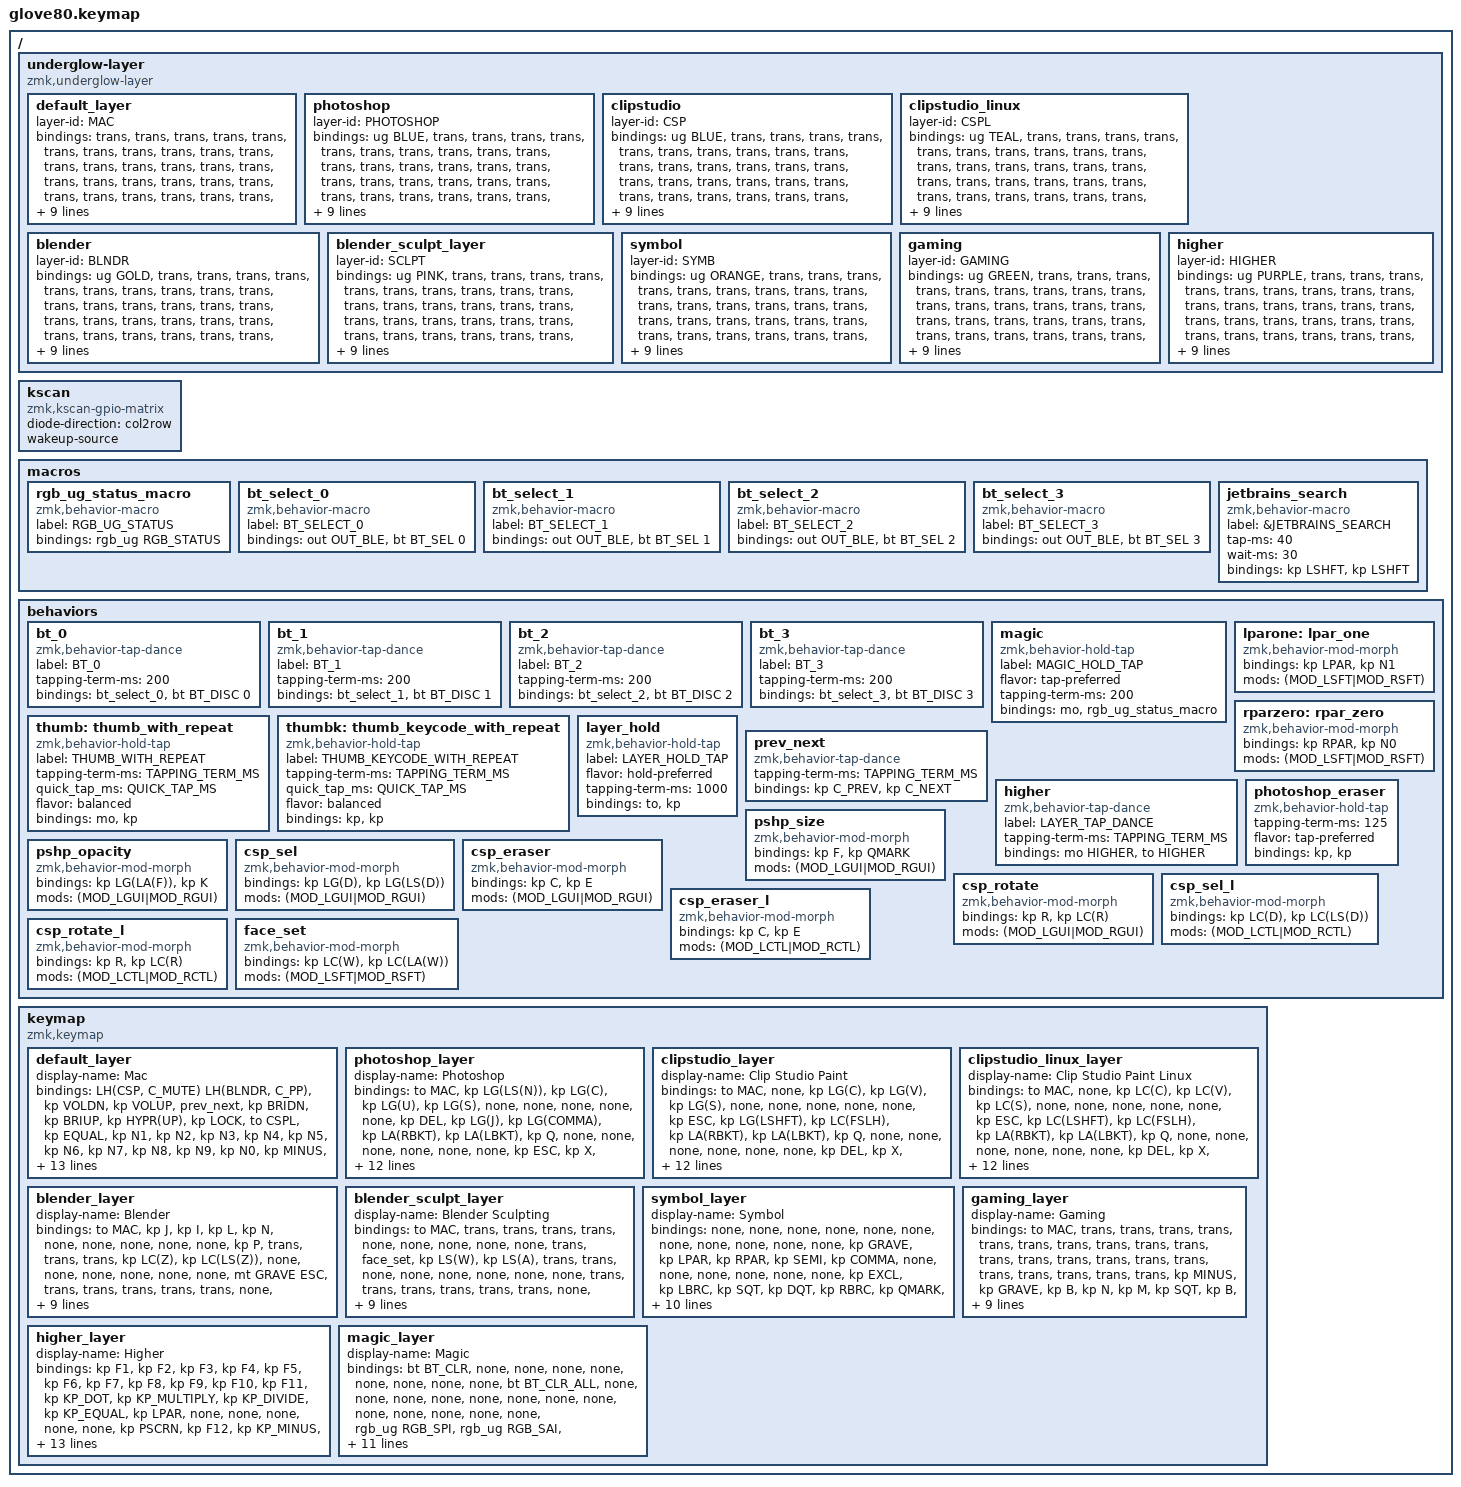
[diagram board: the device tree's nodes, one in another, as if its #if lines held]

/*
 * Copyright (c) 2020 The ZMK Contributors
 * Copyright (c) 2023 Innaworks Development Limited, trading as MoErgo
 *
 * SPDX-License-Identifier: MIT
 */


#include <behaviors.dtsi>
/* Include all behavior includes needed */
#include <dt-bindings/zmk/outputs.h>
#include <dt-bindings/zmk/keys.h>
#include <dt-bindings/zmk/bt.h>
#include <dt-bindings/zmk/rgb.h>
#include <dt-bindings/zmk/rgb_colors.h>
#include <dt-bindings/zmk/ext_power.h>

#define MEH LC(LS(LALT))
#define MEH(KC) LC(LS(LA(KC)))

#define HYPER LC(LS(LG(LALT)))
#define HYPR(KC) LC(LS(LG(LA(KC))))

#define HYPER_W LC(LS(LG(LA(W))))
#define HYPER_E LC(LS(LG(LA(E))))
#define HYPER_UP LC(LS(LG(LA(UP))))

#define LH(layer, keycode) &layer_hold layer keycode
#define BRIUP C_BRI_UP
#define BRIDN C_BRI_DN
#define VOLUP C_VOL_UP
#define VOLDN C_VOL_DN
#define LOCK LG(LC(Q))
#define LANG LC(LS(LG(LA(SPACE))))

#define LEFT_HAND_KEYS      \
      0  1  2  3  4         \
     10 11 12 13 14 15      \
     22 23 24 25 26 27      \
     34 35 36 37 38 39      \
     46 47 48 49 50 51      \
     64 65 66 67 68
#define                              RIGHT_HAND_KEYS \
                                       5  6  7  8  9 \
                                   16 17 18 19 20 21 \
                                   28 29 30 31 32 33 \
                                   40 41 42 43 44 45 \
                                   58 59 60 61 62 63 \
                                      75 76 77 78 79
#define THUMB_KEYS          \
                    69 52       57 74                \
                     70 53     56 73                 \
                      71 54   55 72

#define TAPPING_TERM_MS 200
#define QUICK_TAP_MS 220
#define PRIOR_IDLE_MS 180

//
// Base layers.
//
#define MAC 0        // Default layer
//#define LOWER 1      // Generic lowest layer
//#define LINUX 10   // Linux keys
//
// Workflow layers.
//
#define PHOTOSHOP 1  // Photoshop
#define CSP       2  // Clip Studio Paint for Mac
#define CSPL      3  // Clip Studio Paint for Linux and Windows
#define BLNDR 4      // Blender
#define SCLPT 5      // Blender Sculpting
//#define BLDR2 40   // Blender 2nd layer
//#define BLNM 50    // Blender number input layer
//#define CODE 60    // Used for programming. Slight variation on the MAC layer.
//
// Utility layers.
//
#define SYMB 6       // symbols
#define GAMING 7     // gaming
//#define NUMS 80    // Turns num keys into numbers
//#define MDIA 90    // media keys
//#define MVMT 100   // Cursor movement and selection

/* To deal with the situation where there is no Higher layer, to keep &higher happy */
#ifndef HIGHER
#define HIGHER 8     // Generic highest layer
#endif

#define MAGIC 9      // Keyboard-specific config keys


/* Custom Device-tree */
/* Empty underglow layer definition (for copy-paste)
        mylayer {
            layer-id = <LAYER_Name>;
            bindings = <
                &trans &trans &trans &trans &trans                                                          &trans &trans &trans &trans &trans
                &trans &trans &trans &trans &trans &trans                                            &trans &trans &trans &trans &trans &trans
                &trans &trans &trans &trans &trans &trans                                            &trans &trans &trans &trans &trans &trans
                &trans &trans &trans &trans &trans &trans                                            &trans &trans &trans &trans &trans &trans
                &trans &trans &trans &trans &trans &trans &trans &trans &trans  &trans &trans &trans &trans &trans &trans &trans &trans &trans
                &trans &trans &trans &trans &trans        &trans &trans &trans  &trans &trans &trans        &trans &trans &trans &trans &trans
                >;
        };
*/
/ {
    underglow-layer {
        compatible  = "zmk,underglow-layer";

        default_layer {
            layer-id = <MAC>;
            bindings = <
                &trans &trans &trans &trans &trans                                                          &trans &trans &trans &trans &trans
                &trans &trans &trans &trans &trans &trans                                            &trans &trans &trans &trans &trans &trans
                &trans &trans &trans &trans &trans &trans                                            &trans &trans &trans &trans &trans &trans
                &trans &trans &trans &trans &trans &trans                                            &trans &trans &trans &trans &trans &trans
                &trans &trans &trans &trans &trans &trans &trans &trans &trans  &trans &trans &trans &trans &trans &trans &trans &trans &trans
                &trans &trans &trans &trans &trans        &trans &trans &trans  &trans &trans &trans        &trans &trans &trans &trans &trans
                >;
        };

        photoshop {
            layer-id = <PHOTOSHOP>;
            bindings = <
                &ug BLUE &trans &trans &trans &trans                                                          &trans &trans &trans &trans &trans
                &trans   &trans &trans &trans &trans &trans                                            &trans &trans &trans &trans &trans &trans
                &trans   &trans &trans &trans &trans &trans                                            &trans &trans &trans &trans &trans &trans
                &trans   &trans &trans &trans &trans &trans                                            &trans &trans &trans &trans &trans &trans
                &trans   &trans &trans &trans &trans &trans &trans &trans &trans  &trans &trans &trans &trans &trans &trans &trans &trans &trans
                &trans   &trans &trans &trans &trans        &trans &trans &trans  &trans &trans &trans        &trans &trans &trans &trans &trans
                >;
        };
        clipstudio {
            layer-id = <CSP>;
            bindings = <
                &ug BLUE &trans &trans &trans &trans                                                          &trans &trans &trans &trans &trans
                &trans   &trans &trans &trans &trans &trans                                            &trans &trans &trans &trans &trans &trans
                &trans   &trans &trans &trans &trans &trans                                            &trans &trans &trans &trans &trans &trans
                &trans   &trans &trans &trans &trans &trans                                            &trans &trans &trans &trans &trans &trans
                &trans   &trans &trans &trans &trans &trans &trans &trans &trans  &trans &trans &trans &trans &trans &trans &trans &trans &trans
                &trans   &trans &trans &trans &trans        &trans &trans &trans  &trans &trans &trans        &trans &trans &trans &trans &trans
                >;
        };
        clipstudio_linux {
            layer-id = <CSPL>;
            bindings = <
                &ug TEAL &trans &trans &trans &trans                                                          &trans &trans &trans &trans &trans
                &trans   &trans &trans &trans &trans &trans                                            &trans &trans &trans &trans &trans &trans
                &trans   &trans &trans &trans &trans &trans                                            &trans &trans &trans &trans &trans &trans
                &trans   &trans &trans &trans &trans &trans                                            &trans &trans &trans &trans &trans &trans
                &trans   &trans &trans &trans &trans &trans &trans &trans &trans  &trans &trans &trans &trans &trans &trans &trans &trans &trans
                &trans   &trans &trans &trans &trans        &trans &trans &trans  &trans &trans &trans        &trans &trans &trans &trans &trans
                >;
        };
        blender {
            layer-id = <BLNDR>;
            bindings = <
                &ug GOLD &trans &trans &trans &trans                                                          &trans &trans &trans &trans &trans
                &trans   &trans &trans &trans &trans &trans                                            &trans &trans &trans &trans &trans &trans
                &trans   &trans &trans &trans &trans &trans                                            &trans &trans &trans &trans &trans &trans
                &trans   &trans &trans &trans &trans &trans                                            &trans &trans &trans &trans &trans &trans
                &trans   &trans &trans &trans &trans &trans &trans &trans &trans  &trans &trans &trans &trans &trans &trans &trans &trans &trans
                &trans   &trans &trans &trans &trans        &trans &trans &trans  &trans &trans &trans        &trans &trans &trans &trans &trans
                >;
        };
        blender_sculpt_layer {
            layer-id = <SCLPT>;
            bindings = <
                &ug PINK &trans &trans &trans &trans                                                          &trans &trans &trans &trans &trans
                &trans   &trans &trans &trans &trans &trans                                            &trans &trans &trans &trans &trans &trans
                &trans   &trans &trans &trans &trans &trans                                            &trans &trans &trans &trans &trans &trans
                &trans   &trans &trans &trans &trans &trans                                            &trans &trans &trans &trans &trans &trans
                &trans   &trans &trans &trans &trans &trans &trans &trans &trans  &trans &trans &trans &trans &trans &trans &trans &trans &trans
                &trans   &trans &trans &trans &trans        &trans &trans &trans  &trans &trans &trans        &trans &trans &trans &trans &trans
                >;
        };
        symbol {
            layer-id = <SYMB>;
            bindings = <
                &ug ORANGE &trans &trans &trans &trans                                                          &trans &trans &trans &trans &trans
                &trans     &trans &trans &trans &trans &trans                                            &trans &trans &trans &trans &trans &trans
                &trans     &trans &trans &trans &trans &trans                                            &trans &trans &trans &trans &trans &trans
                &trans     &trans &trans &trans &trans &trans                                            &trans &trans &trans &trans &trans &trans
                &trans     &trans &trans &trans &trans &trans &trans &trans &trans  &trans &trans &trans &trans &trans &trans &trans &trans &trans
                &trans     &trans &trans &trans &trans        &trans &trans &trans  &trans &trans &trans        &trans &trans &trans &trans &trans
                >;
        };
        gaming {
            layer-id = <GAMING>;
            bindings = <
                &ug GREEN &trans &trans &trans &trans                                                          &trans &trans &trans &trans &trans
                &trans    &trans &trans &trans &trans &trans                                            &trans &trans &trans &trans &trans &trans
                &trans    &trans &trans &trans &trans &trans                                            &trans &trans &trans &trans &trans &trans
                &trans    &trans &trans &trans &trans &trans                                            &trans &trans &trans &trans &trans &trans
                &trans    &trans &trans &trans &trans &trans &trans &trans &trans  &trans &trans &trans &trans &trans &trans &trans &trans &trans
                &trans    &trans &trans &trans &trans        &trans &trans &trans  &trans &trans &trans        &trans &trans &trans &trans &trans
                >;
        };
        higher {
            layer-id = <HIGHER>;
            bindings = <
                &ug PURPLE &trans &trans &trans &trans                                                          &trans &trans &trans &trans &trans
                &trans     &trans &trans &trans &trans &trans                                            &trans &trans &trans &trans &trans &trans
                &trans     &trans &trans &trans &trans &trans                                            &trans &trans &trans &trans &trans &trans
                &trans     &trans &trans &trans &trans &trans                                            &trans &trans &trans &trans &trans &trans
                &trans     &trans &trans &trans &trans &trans &trans &trans &trans  &trans &trans &trans &trans &trans &trans &trans &trans &trans
                &trans     &trans &trans &trans &trans        &trans &trans &trans  &trans &trans &trans        &trans &trans &trans &trans &trans
                >;
        };
    };
};

// Deep Sleep support
/ {
    kscan: kscan {
        compatible = "zmk,kscan-gpio-matrix";
        diode-direction = "col2row";
        wakeup-source;
    };
};

/* Glove80 system behavior & macros */
/ {
    macros {
        rgb_ug_status_macro: rgb_ug_status_macro {
            label = "RGB_UG_STATUS";
            compatible = "zmk,behavior-macro";
            #binding-cells = <0>;
            bindings
                = <&rgb_ug RGB_STATUS>;
        };
    };
};


/ {
#ifdef BT_DISC_CMD
    behaviors {
        bt_0: bt_0 {
            compatible = "zmk,behavior-tap-dance";
            label = "BT_0";
            #binding-cells = <0>;
            tapping-term-ms = <200>;
            bindings = <&bt_select_0>, <&bt BT_DISC 0>;
        };
        bt_1: bt_1 {
            compatible = "zmk,behavior-tap-dance";
            label = "BT_1";
            #binding-cells = <0>;
            tapping-term-ms = <200>;
            bindings = <&bt_select_1>, <&bt BT_DISC 1>;
        };
        bt_2: bt_2 {
            compatible = "zmk,behavior-tap-dance";
            label = "BT_2";
            #binding-cells = <0>;
            tapping-term-ms = <200>;
            bindings = <&bt_select_2>, <&bt BT_DISC 2>;
        };
        bt_3: bt_3 {
            compatible = "zmk,behavior-tap-dance";
            label = "BT_3";
            #binding-cells = <0>;
            tapping-term-ms = <200>;
            bindings = <&bt_select_3>, <&bt BT_DISC 3>;
        };
    };
    macros {
        bt_select_0: bt_select_0 {
            label = "BT_SELECT_0";
            compatible = "zmk,behavior-macro";
            #binding-cells = <0>;
            bindings
                = <&out OUT_BLE>,
                  <&bt BT_SEL 0>;
        };
        bt_select_1: bt_select_1 {
            label = "BT_SELECT_1";
            compatible = "zmk,behavior-macro";
            #binding-cells = <0>;
            bindings
                = <&out OUT_BLE>,
                  <&bt BT_SEL 1>;
        };
        bt_select_2: bt_select_2 {
            label = "BT_SELECT_2";
            compatible = "zmk,behavior-macro";
            #binding-cells = <0>;
            bindings
                = <&out OUT_BLE>,
                  <&bt BT_SEL 2>;
        };
        bt_select_3: bt_select_3 {
            label = "BT_SELECT_3";
            compatible = "zmk,behavior-macro";
            #binding-cells = <0>;
            bindings
                = <&out OUT_BLE>,
                  <&bt BT_SEL 3>;
        };
    };
#else
    macros {
        bt_0: bt_0 {
            label = "BT_0";
            compatible = "zmk,behavior-macro";
            #binding-cells = <0>;
            bindings
                = <&out OUT_BLE>,
                  <&bt BT_SEL 0>;
        };
        bt_1: bt_1 {
            label = "BT_1";
            compatible = "zmk,behavior-macro";
            #binding-cells = <0>;
            bindings
                = <&out OUT_BLE>,
                  <&bt BT_SEL 1>;
        };
        bt_2: bt_2 {
            label = "BT_2";
            compatible = "zmk,behavior-macro";
            #binding-cells = <0>;
            bindings
                = <&out OUT_BLE>,
                  <&bt BT_SEL 2>;
        };
        bt_3: bt_3 {
            label = "BT_3";
            compatible = "zmk,behavior-macro";
            #binding-cells = <0>;
            bindings
                = <&out OUT_BLE>,
                  <&bt BT_SEL 3>;
        };
    };
#endif
};

/ {
    behaviors {
        magic: magic {
            compatible = "zmk,behavior-hold-tap";
            label = "MAGIC_HOLD_TAP";
            #binding-cells = <2>;
            flavor = "tap-preferred";
            tapping-term-ms = <200>;
            bindings = <&mo>, <&rgb_ug_status_macro>;
        };
    };
};

/* #define for key positions */
#define POS_LH_T1 52
#define POS_LH_T2 53
#define POS_LH_T3 54
#define POS_LH_T4 69
#define POS_LH_T5 70
#define POS_LH_T6 71
#define POS_LH_C1R2 15
#define POS_LH_C1R3 27
#define POS_LH_C1R4 39
#define POS_LH_C1R5 51
#define POS_LH_C2R1 4
#define POS_LH_C2R2 14
#define POS_LH_C2R3 26
#define POS_LH_C2R4 38
#define POS_LH_C2R5 50
#define POS_LH_C2R6 68
#define POS_LH_C3R1 3
#define POS_LH_C3R2 13
#define POS_LH_C3R3 25
#define POS_LH_C3R4 37
#define POS_LH_C3R5 49
#define POS_LH_C3R6 67
#define POS_LH_C4R1 2
#define POS_LH_C4R2 12
#define POS_LH_C4R3 24
#define POS_LH_C4R4 36
#define POS_LH_C4R5 48
#define POS_LH_C4R6 66
#define POS_LH_C5R1 1
#define POS_LH_C5R2 11
#define POS_LH_C5R3 23
#define POS_LH_C5R4 35
#define POS_LH_C5R5 47
#define POS_LH_C5R6 65
#define POS_LH_C6R1 0
#define POS_LH_C6R2 10
#define POS_LH_C6R3 22
#define POS_LH_C6R4 34
#define POS_LH_C6R5 46
#define POS_LH_C6R6 64
#define POS_RH_T1 57
#define POS_RH_T2 56
#define POS_RH_T3 55
#define POS_RH_T4 74
#define POS_RH_T5 73
#define POS_RH_T6 72
#define POS_RH_C1R2 16
#define POS_RH_C1R3 28
#define POS_RH_C1R4 40
#define POS_RH_C1R5 58
#define POS_RH_C2R1 5
#define POS_RH_C2R2 17
#define POS_RH_C2R3 29
#define POS_RH_C2R4 41
#define POS_RH_C2R5 59
#define POS_RH_C2R6 75
#define POS_RH_C3R1 6
#define POS_RH_C3R2 18
#define POS_RH_C3R3 30
#define POS_RH_C3R4 42
#define POS_RH_C3R5 60
#define POS_RH_C3R6 76
#define POS_RH_C4R1 7
#define POS_RH_C4R2 19
#define POS_RH_C4R3 31
#define POS_RH_C4R4 43
#define POS_RH_C4R5 61
#define POS_RH_C4R6 77
#define POS_RH_C5R1 8
#define POS_RH_C5R2 20
#define POS_RH_C5R3 32
#define POS_RH_C5R4 44
#define POS_RH_C5R5 62
#define POS_RH_C5R6 78
#define POS_RH_C6R1 9
#define POS_RH_C6R2 21
#define POS_RH_C6R3 33
#define POS_RH_C6R4 45
#define POS_RH_C6R5 63
#define POS_RH_C6R6 79

/* Custom Defined Behaviors */
/ {
    behaviors {
        lparone: lpar_one {
            compatible = "zmk,behavior-mod-morph";
            #binding-cells = <0>;
            bindings = <&kp LPAR>, <&kp N1>;
            mods = <(MOD_LSFT|MOD_RSFT)>;
        };
        rparzero: rpar_zero {
            compatible = "zmk,behavior-mod-morph";
            #binding-cells = <0>;
            bindings = <&kp RPAR>, <&kp N0>;
            mods = <(MOD_LSFT|MOD_RSFT)>;
        };
        // thumb and thumbk allow double tapping a key to get repeat on the tap key, while supporting hold triggering a different key or layer.
        thumb: thumb_with_repeat {
            compatible = "zmk,behavior-hold-tap";
            label = "THUMB_WITH_REPEAT";
            #binding-cells = <2>;
            tapping-term-ms = <TAPPING_TERM_MS>;
            quick_tap_ms = <QUICK_TAP_MS>;
            //require-prior-idle-ms = <PRIOR_IDLE_MS>;
            flavor = "balanced";
            bindings = <&mo>, <&kp>;
        };
        thumbk: thumb_keycode_with_repeat {
            compatible = "zmk,behavior-hold-tap";
            label = "THUMB_KEYCODE_WITH_REPEAT";
            #binding-cells = <2>;
            tapping-term-ms = <TAPPING_TERM_MS>;
            quick_tap_ms = <QUICK_TAP_MS>;
            //require-prior-idle-ms = <PRIOR_IDLE_MS>;
            flavor = "balanced";
            bindings = <&kp>, <&kp>;
        };
        layer_hold: layer_hold {
            compatible = "zmk,behavior-hold-tap";
            label = "LAYER_HOLD_TAP";
            #binding-cells = <2>;
            flavor = "hold-preferred";
            tapping-term-ms = <1000>;
            bindings = <&to>, <&kp>;
        };
        prev_next: prev_next {
            compatible = "zmk,behavior-tap-dance";
            tapping-term-ms = <TAPPING_TERM_MS>;
            #binding-cells = <0>;
            bindings = <&kp C_PREV>, <&kp C_NEXT>;
        };
        // For the "layer" key, it'd nice to be able to use it as either a shift or a toggle.
        // Configure it as a tap dance, so the first tap (or hold) is a &mo and the second tap is a &to
        higher: higher {
            compatible = "zmk,behavior-tap-dance";
            label = "LAYER_TAP_DANCE";
            tapping-term-ms = <TAPPING_TERM_MS>;
            #binding-cells = <0>;
            bindings = <&mo HIGHER>, <&to HIGHER>;
        };
        photoshop_eraser: photoshop_eraser {
            compatible = "zmk,behavior-hold-tap";
            tapping-term-ms = <125>;
            flavor = "tap-preferred";
            #binding-cells = <2>;
            bindings = <&kp>, <&kp>;
        };
        pshp_size: pshp_size {
            compatible = "zmk,behavior-mod-morph";
            #binding-cells = <0>;
            bindings = <&kp F>, <&kp QMARK>;
            mods = <(MOD_LGUI|MOD_RGUI)>;
        };
        pshp_opacity: pshp_opacity {
            compatible = "zmk,behavior-mod-morph";
            #binding-cells = <0>;
            bindings = <&kp LG(LA(F))>, <&kp K>;
            mods = <(MOD_LGUI|MOD_RGUI)>;
        };
        // Clip Studio Paint MAC: Deselect and Reselect
        csp_sel: csp_sel {
            compatible = "zmk,behavior-mod-morph";
            #binding-cells = <0>;
            bindings = <&kp LG(D)>, <&kp LG(LS(D))>;
            mods = <(MOD_LGUI|MOD_RGUI)>;
        };
        // Clip Studio Paint MAC: Transparent Brush and Eraser
        csp_eraser: csp_eraser {
            compatible = "zmk,behavior-mod-morph";
            #binding-cells = <0>;
            bindings = <&kp C>, <&kp E>;
            mods = <(MOD_LGUI|MOD_RGUI)>;
        };
        // Clip Studio Paint MAC: Rotate and Reset Rotation
        csp_rotate: csp_rotate {
            compatible = "zmk,behavior-mod-morph";
            #binding-cells = <0>;
            bindings = <&kp R>, <&kp LC(R)>;
            mods = <(MOD_LGUI|MOD_RGUI)>;
        };
        // Clip Studio Paint LINUX: Deselect and Reselect
        csp_sel_l: csp_sel_l {
            compatible = "zmk,behavior-mod-morph";
            #binding-cells = <0>;
            bindings = <&kp LC(D)>, <&kp LC(LS(D))>;
            mods = <(MOD_LCTL|MOD_RCTL)>;
        };
        // Clip Studio Paint LINUX: Transparent Brush and Eraser
        csp_eraser_l: csp_eraser_l {
            compatible = "zmk,behavior-mod-morph";
            #binding-cells = <0>;
            bindings = <&kp C>, <&kp E>;
            mods = <(MOD_LCTL|MOD_RCTL)>;
        };
        // Clip Studio Paint LINUX: Rotate and Reset Rotation
        csp_rotate_l: csp_rotate_l {
            compatible = "zmk,behavior-mod-morph";
            #binding-cells = <0>;
            bindings = <&kp R>, <&kp LC(R)>;
            mods = <(MOD_LCTL|MOD_RCTL)>;
        };
        // Blender Sculpting Grow/Shrink Face Set
        face_set: face_set {
            compatible = "zmk,behavior-mod-morph";
            #binding-cells = <0>;
            bindings = <&kp LC(W)>, <&kp LC(LA(W))>;
            mods = <(MOD_LSFT|MOD_RSFT)>;
        };
    };

};

/* Automatically generated macro definitions */
/ {
    macros {
        jetbrains_search: jetbrains_search {
            label = "&JETBRAINS_SEARCH";
            compatible = "zmk,behavior-macro";
            #binding-cells = <0>;
            tap-ms = <40>;
            wait-ms = <30>;
            bindings = <&kp LSHFT>
                     , <&kp LSHFT>;
        };
    };
};

/* Automatically generated keymap */
/ {
    keymap {
        compatible = "zmk,keymap";

        // MEH  = ctrl + shift + alt
        // HYPR = ctrl + shift + alt + gui
        default_layer {
            display-name = "Mac";
            bindings = <
            LH(CSP, C_MUTE) LH(BLNDR, C_PP) &kp VOLDN  &kp VOLUP &prev_next                                                                                                                 &kp BRIDN &kp BRIUP &kp HYPR(UP) &kp LOCK &to CSPL
            &kp EQUAL       &kp N1          &kp N2     &kp N3    &kp N4    &kp N5                                                                                                 &kp N6    &kp N7    &kp N8    &kp N9   &kp N0       &kp MINUS
            &kp LANG        &kp Q           &kp W      &kp E     &kp R     &kp T                                                                                                  &kp Y     &kp U     &kp I     &kp O    &kp P        &kp BSLH
            &mt LSHFT TAB   &kp A           &kp S      &kp D     &kp F     &kp G                                                                                                  &kp H     &kp J     &kp K     &kp L    &kp SEMI     &kp SQT
            &kp GRAVE       &kp Z           &kp X      &kp C     &kp V     &kp B  &kp LGUI            &kp RA(RET)        &kp LSHFT        &kp LCTRL     &kp RALT        &kp ESC   &kp N     &kp M     &kp COMMA &kp DOT  &kp FSLH     &kp PG_UP
            &magic MAGIC 0  &key_repeat     &kp LBKT   &kp LBRC  &lparone         &thumb HIGHER SPACE &thumbk LCTRL BSPC &thumbk LALT DEL &kp LG(LSHFT) &thumb SYMB RET &kp LSHFT &rparzero &kp RBRC  &kp RBKT &kp EXCL  &kp PG_DN
            >;
        };

//        just to use as a template
//        the reason being that defaulting to &none prevents accidentally activating keys due to active underlying layers being dependent on what layers I've activated at that point in time.
//        template_layer {
//            display-name = "Template";
//            bindings = <
//            &none &none &none &none &none                                                 &none &none &none &none &none
//            &none &none &none &none &none &none                                     &none &none &none &none &none &none
//            &none &none &none &none &none &none                                     &none &none &none &none &none &none
//            &none &none &none &none &none &none                                     &none &none &none &none &none &none
//            &none &none &none &none &none &none &none &none &none &none &none &none &none &none &none &none &none &none
//            &none &none &none &none &none       &none &none &none &none &none &none       &none &none &none &none &none
//            >;
//        };

        // Photoshop
        // ---------
        // cmd + d - deselect selection
        // cmd + j - layer via copy
        // cmd + , - hide layer
        // alt + [ - cycle visible layers backward
        // alt + ] - cycle visible layers foreward
        // cmd + t - free transform selection
        // alt + backspace - fill selection with chosen foreground color (the primary color selection)
        // cmd + backspace - fill selection with chosen background color (the secondary color selection)
        // hold grave - erase with current brush
        // cmd + y  - View > Proof Colors (to see color values only)
        // cmd + shift + n - new layer
        // shift - make straight lines
        // ctrl + click - brush selection
        // F5 - brush settings
        // ctrl + alt - click and drag to dynamically change brush/eraser size and hardness (drag left/right for brush size, up/down for hardness)
        // shift + tool shortcut - cycle between tools of that type (between brush and mixer brush, etc.)
        // cmd + ctrl + click - layer selection menu for layers under the mouse cursor
        // cmd + click - select layer for topmost layer under the mouse cursor
        // q - quick mask mode
        // tab - toggle tools (useful for fullscreen mode)
        //
        // Layers
        // ------
        // cmd + m - Curves
        // cmd + l - Levels
        // cmd + u - Hue/Saturation
        // cmd + b - Color Balance
        // alt + click between layers - convert layer into a clipping mask
        // cmd + click layer - select everything in the layer
        // cmd + shift + click layer - add everything in layer to the current selection
        // slash - lock transparent pixels on the layer
        //
        // My custom shortcuts
        // --------------------
        // cmd + alt + f - Flip Canvas Horizontally
        // K - toggle pen pressure brush opacity (had to remove the existing K shortcut to be able to set this one)
        // ? - toggle pen pressure brush size
        photoshop_layer {
            display-name = "Photoshop";
            bindings = <
            &to MAC        &kp LG(LS(N)) &kp LG(C)     &kp LG(U)                 &kp LG(S)                                                                                                 &none &none &none &none &none
            &kp DEL        &kp LG(J)     &kp LG(COMMA) &kp LA(RBKT)              &kp LA(LBKT)  &kp Q                                                                                 &none &none &none &none &none &none
            &kp ESC        &kp X         &kp LG(D)     &kp SPACE                 &kp LG(Z)     &kp LG(LS(Z))                                                                         &none &none &none &none &none &none
            &mt LCTRL F5   &kp L         &kp V         &photoshop_eraser GRAVE E &kp B         &kp LALT                                                                              &none &none &none &none &none &none
            &kp M          &kp LSHFT     &kp LG(A)     &kp R                     &kp Z         &kp LG(Y)     &higher           &kp FSLH       &kp TAB              &none &none &none &none &none &none &none &none &none
            &magic MAGIC 0 &kp LA(BSPC)  &kp LG(T)     &pshp_size                &pshp_opacity               &mt LC(LALT) LBKT &mt LGUI RBKT  &kp RET              &none &none &none       &none &none &none &none &none
            >;
        };

        // Clip Studio Paint
        // -----------------
        // C - switch to painting transparent color using current brush (aka erase)
        // J - Liquify tool
        // A - airbrush
        // S - sketch pencils
        // P - paint brushes
        // M - Selection Area (first subtool is Lasso)
        // comma, period - next/previous subtool
        // cmd + alt + g - clip to layer below (toggle layer as clipping mask)
        //
        // My custom hotkeys
        // -----------------
        // Q - quick mask
        // cmd + comma - show/hide layer
        // cmd + shift + click canvas - select layer for pixel under the mouse cursor
        // cmd + alt + f - flip canvas horizontally
        // slash - lock transparent pixels on the layer
        // ctrl + slash  - lock layer
        // ctrl + r  - reset rotation
        // meh + s - (removed) show/hide subtool panel
        //
        // Unused hotkeys (not set below but customized in my CSP)
        // --------------
        // cmd + alt + left bracket  - decrease brush hardness
        // cmd + alt + right bracket - increase brush hardness
        // cmd + j - copy and paste (layer via copy in Photoshop) (found in the "Shortcut Settings -> Category: Options -> Edit" menu)
        //
        // Needs
        // -----
        // ...
        clipstudio_layer {
            display-name = "Clip Studio Paint";
            bindings = <
            &to MAC        &none         &kp LG(C)     &kp LG(V)    &kp LG(S)                                                                                                &none &none &none &none &none
            &kp ESC        &kp LG(LSHFT) &kp LC(FSLH)  &kp LA(RBKT) &kp LA(LBKT) &kp Q                                                                                 &none &none &none &none &none &none
            &kp DEL        &kp X         &csp_sel      &kp SPACE    &kp LG(Z)    &kp LG(LS(Z))                                                                         &none &none &none &none &none &none
            &mt LCTRL W    &kp M         &kp O         &csp_eraser  &kp P        &kp B                                                                                 &none &none &none &none &none &none
            &kp S          &kp J         &mt LSHFT A   &csp_rotate  &kp Z        &kp LG(LA(F)) &kp LALT          &kp LG(COMMA)  &kp TAB              &none &none &none &none &none &none &none &none &none
            &magic MAGIC 0 &kp LA(BSPC)  &kp LG(T)     &kp COMMA    &kp DOT                    &mt LG(LALT) LBKT &mt LGUI RBKT  &kp RET              &none &none &none       &none &none &none &none &none
            >;
        };
        clipstudio_linux_layer {
            display-name = "Clip Studio Paint Linux";
            bindings = <
            &to MAC        &none         &kp LC(C)     &kp LC(V)      &kp LC(S)                                                                                                &none &none &none &none &none
            &kp ESC        &kp LC(LSHFT) &kp LC(FSLH)  &kp LA(RBKT)   &kp LA(LBKT) &kp Q                                                                                 &none &none &none &none &none &none
            &kp DEL        &kp X         &csp_sel_l    &kp SPACE      &kp LC(Z)    &kp LC(LS(Z))                                                                         &none &none &none &none &none &none
            &mt LCTRL W    &kp M         &kp O         &csp_eraser_l  &kp P        &kp B                                                                                 &none &none &none &none &none &none
            &kp S          &kp J         &mt LSHFT A   &csp_rotate_l  &kp Z        &kp LC(LA(F)) &kp LALT          &kp LC(COMMA)   &kp TAB             &none &none &none &none &none &none &none &none &none
            &magic MAGIC 0 &kp LA(BSPC)  &kp LC(T)     &kp COMMA      &kp DOT                    &mt LC(LALT) LBKT &mt LCTRL RBKT  &kp RET             &none &none &none       &none &none &none &none &none
            >;
        };

        // needed:
        // slash
        // period/dot (median/origin point)
        // p for parenting
        // n key to open/close tool menu
        // m to add marker in timeline and join vertices (alt+m)
        // h for hide
        // j to join
        // alt + q - select object in sculpt mode
        blender_layer {
            display-name = "Blender";
            bindings = <
            &to MAC        &kp J   &kp I  &kp L  &kp N                                                                                           &none &none &none &none &none
            &kp P          &trans  &trans &trans &kp LC(Z) &kp LC(LS(Z))                                                                   &none &none &none &none &none &none
            &mt GRAVE ESC  &trans  &trans &trans &trans    &trans                                                                          &none &none &none &none &none &none
            &kp TAB        &trans  &trans &trans &trans    &trans                                                                          &none &none &none &none &none &none
            &kp Y          &trans  &trans &trans &trans    &trans &kp LALT  &thumb SYMB LC(LA(KP_N0)) &tog SCLPT         &none &none &none &none &none &none &none &none &none
            &magic MAGIC 0 &kp DOT &kp H  &kp O  &kp M            &kp LSHFT &kp LCTL                  &higher            &none &none &none       &none &none &none &none &none
            >;
        };

        // hotkeys on the keyboard
        // -------
        // ctrl + w - grow face set
        // ctrl + alt + w - shrink face set
        // shift + w - expand face set by topology
        // shift + a - expand mask by topology

        // things I should put on my spacemouse menus
        // -------
        // undo
        // redo
        // save
        // f - used for:
        //     - brush size
        //     - shift + f can be achieved by using the combination of f on the pen with shift on the spacemouse
        // a - mask edit menu
        // shift + a - expand mask by topology
        // shift alt a - expand mask by normals
        // alt + w - face set edit menu
        // shift + w - expand face set by topology
        // shift + alt + w - expand active face set
        // slash
        // a - mask edit menu
        // w
        // h
        // q
        // e
        // b
        // d
        // i
        // j

        // less critical for space mouse:
        // -------
        // c
        // v
        // t
        // m
        // l
        // p
        // right click - used for:
        //     - brush menu
        //     - ctrl + right click - lasso remove mask
        //     - shift + right click - sets pivot point to the vertex under the mouse cursor

        blender_sculpt_layer {
            display-name = "Blender Sculpting";
            bindings = <
            &to MAC        &trans    &trans    &trans    &trans                                                                         &none &none &none &none &none
            &trans         &face_set &kp LS(W) &kp LS(A) &trans &trans                                                            &none &none &none &none &none &none
            &trans         &trans    &trans    &trans    &trans &trans                                                            &none &none &none &none &none &none
            &trans         &trans    &trans    &trans    &trans &trans                                                            &none &none &none &none &none &none
            &trans         &trans    &trans    &trans    &trans &trans &trans &trans &tog SCLPT                 &none &none &none &none &none &none &none &none &none
            &magic MAGIC 0 &trans    &trans    &trans    &trans        &trans &trans &trans                     &none &none &none       &none &none &none &none &none
            >;
        };

        symbol_layer {
            display-name = "Symbol";
            bindings = <
            &none     &none     &none     &none     &none                                                                          &none     &none       &none     &none    &none
            &none     &kp GRAVE &kp LPAR  &kp RPAR  &kp SEMI &kp COMMA                                                    &none    &none     &none       &none     &none    &none
            &kp EXCL  &kp LBRC  &kp SQT   &kp DQT   &kp RBRC &kp QMARK                                                    &kp SEMI &kp RSHFT &kp RCTRL   &kp RALT  &kp RGUI &none
            &kp HASH  &kp CARET &kp EQUAL &kp UNDER &kp DLLR &kp STAR                                                     &kp DOT  &kp BSPC  &kp TAB     &kp SPACE &kp RET  &none
            &kp TILDE &kp LT    &kp PIPE  &kp MINUS &kp GT   &kp FSLH  &kp BSLH  &kp DOT   &kp STAR     &none &none &none &kp FSLH &kp DEL   &kp LS(TAB) &none     &none    &none
            &kp AT    &kp AMPS  &kp LBKT  &kp RBKT  &kp PLUS           &kp PRCNT &kp COLON &kp SEMI     &to 0 &none &none          &trans    &trans      &trans    &trans   &none
            >;
        };

        gaming_layer {
            display-name = "Gaming";
            bindings = <
            &to MAC   &trans    &trans &trans &trans                                                                               &trans &trans &trans    &trans  &trans
            &trans    &trans    &trans &trans &trans &trans                                                                 &trans &trans &trans &trans    &trans  &trans
            &kp MINUS &kp GRAVE &kp B  &kp N  &kp M  &kp SQT                                                                &kp B  &kp N  &kp M  &kp COMMA &kp DOT &kp FSLH
            &kp T     &kp TAB   &kp Q  &kp W  &kp E  &kp R                                                                  &kp T  &kp Y  &kp U  &kp I     &kp O   &kp P
            &kp G     &kp LSHFT &kp A  &kp S  &kp D  &kp F   &kp ESC   &kp RET  &kp PAUSE_BREAK     &kp BSPC &kp DEL &trans &kp G  &kp H  &kp J  &kp K     &kp L   &kp SEMI
            &kp V     &kp LCTRL &kp Z  &kp X  &kp C          &kp SPACE &kp LALT &kp LGUI            &to 0    &trans  &trans        &trans &trans &trans    &trans  &trans
            >;
        };

        higher_layer {
            display-name = "Higher";
            bindings = <
            &kp F1         &kp F2       &kp F3          &kp F4        &kp F5                                                                                     &kp F6      &kp F7      &kp F8       &kp F9  &kp F10
            &kp F11        &kp KP_DOT   &kp KP_MULTIPLY &kp KP_DIVIDE &kp KP_EQUAL &kp LPAR                                                             &none    &none       &none       &none        &none   &kp PSCRN
            &kp F12        &kp KP_MINUS &kp KP_N7       &kp KP_N8     &kp KP_N9    &kp RPAR                                                             &none    &kp HYPR(W) &kp HYPR(E) &kp HYPR(UP) &none   &kp SLCK
            &kp F9         &kp KP_PLUS  &kp KP_N4       &kp KP_N5     &kp KP_N6    &kp PRCNT                                                            &kp LEFT &kp DOWN    &kp UP      &kp RIGHT    &none   &to GAMING
            &none          &kp KP_ENTER &kp KP_N1       &kp KP_N2     &kp KP_N3    &kp COMMA &none  &trans &to MAC     &trans        &trans    &kp LGUI &none    &none       &none       &none        &none   &none
            &magic MAGIC 0 &kp KP_ENTER &kp KP_N0       &kp KP_N0     &kp KP_DOT             &trans &trans &trans      &kp LA(LSHFT) &kp LSHFT &kp LALT          &kp SPACE   &kp BSPC    &kp DEL      &kp RET &none
            >;
        };

        magic_layer {
            display-name = "Magic";
            bindings = <
            &bt BT_CLR  &none           &none           &none           &none                                                                                &none &none &none &none &bt BT_CLR_ALL
            &none       &none           &none           &none           &none           &none                                                          &none &none &none &none &none &none
            &none       &rgb_ug RGB_SPI &rgb_ug RGB_SAI &rgb_ug RGB_HUI &rgb_ug RGB_BRI &rgb_ug RGB_TOG                                                &none &none &none &none &none &none
            &bootloader &rgb_ug RGB_SPD &rgb_ug RGB_SAD &rgb_ug RGB_HUD &rgb_ug RGB_BRD &rgb_ug RGB_EFF                                                &none &none &none &none &none &bootloader
            &sys_reset  &none           &none           &none           &none           &none           &bt_2 &bt_3 &to MAC          &none &none &none &none &none &none &none &none &sys_reset
            &none       &none           &none           &none           &none                           &bt_0 &bt_1 &out OUT_USB     &none &none &none       &none &none &none &none &none
            >;
        };

    };
};
